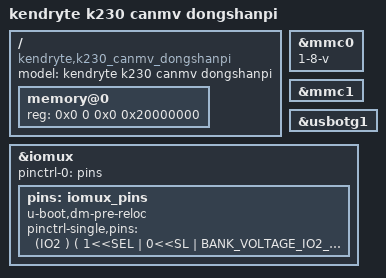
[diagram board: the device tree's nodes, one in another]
/* Copyright (c) 2023, Canaan Bright Sight Co., Ltd
 *
 * Redistribution and use in source and binary forms, with or without
 * modification, are permitted provided that the following conditions are met:
 * 1. Redistributions of source code must retain the above copyright
 * notice, this list of conditions and the following disclaimer.
 * 2. Redistributions in binary form must reproduce the above copyright
 * notice, this list of conditions and the following disclaimer in the
 * documentation and/or other materials provided with the distribution.
 *
 * THIS SOFTWARE IS PROVIDED BY THE COPYRIGHT HOLDERS AND
 * CONTRIBUTORS "AS IS" AND ANY EXPRESS OR IMPLIED WARRANTIES,
 * INCLUDING, BUT NOT LIMITED TO, THE IMPLIED WARRANTIES OF
 * MERCHANTABILITY AND FITNESS FOR A PARTICULAR PURPOSE ARE
 * DISCLAIMED. IN NO EVENT SHALL THE COPYRIGHT HOLDER OR
 * CONTRIBUTORS BE LIABLE FOR ANY DIRECT, INDIRECT, INCIDENTAL,
 * SPECIAL, EXEMPLARY, OR CONSEQUENTIAL DAMAGES (INCLUDING,
 * BUT NOT LIMITED TO, PROCUREMENT OF SUBSTITUTE GOODS OR
 * SERVICES; LOSS OF USE, DATA, OR PROFITS; OR BUSINESS
 * INTERRUPTION) HOWEVER CAUSED AND ON ANY THEORY OF LIABILITY,
 * WHETHER IN CONTRACT, STRICT LIABILITY, OR TORT (INCLUDING
 * NEGLIGENCE OR OTHERWISE) ARISING IN ANY WAY OUT OF THE USE
 * OF THIS SOFTWARE, EVEN IF ADVISED OF THE POSSIBILITY OF SUCH DAMAGE.
 */
/dts-v1/;
#include <dt-bindings/pinctrl/k230_evb.h>

#define BANK_VOLTAGE_IO0_IO1	 K230_MSC_1V8  // FIXED
#define BANK_VOLTAGE_IO2_IO13	 K230_MSC_3V3
#define BANK_VOLTAGE_IO14_IO25	 K230_MSC_3V3
#define BANK_VOLTAGE_IO26_IO37	 K230_MSC_3V3
#define BANK_VOLTAGE_IO38_IO49	 K230_MSC_3V3
#define BANK_VOLTAGE_IO50_IO61	 K230_MSC_3V3
#define BANK_VOLTAGE_IO62_IO63	 K230_MSC_3V3
#include "k230.dtsi"

/ {
	model = "kendryte k230 canmv dongshanpi";
	compatible = "kendryte,k230_canmv_dongshanpi";

	memory@0 {
		device_type = "memory";
		reg = <
				0x0 0 0x0 0x20000000
			  >;
	};
};

&mmc0 {
	1-8-v;
	status = "okay";
};

&mmc1 {
	status = "okay";
};

&usbotg1 {
	status = "okay";
};

&iomux {
	pinctrl-names = "default";
	pinctrl-0 = <&pins>;

//	Please pay attention to the bank voltage! will damage the chip.
	pins: iomux_pins {
		u-boot,dm-pre-reloc;
		pinctrl-single,pins = <

		// JTAG -> J5
		(IO2 ) ( 1<<SEL | 0<<SL | BANK_VOLTAGE_IO2_IO13 <<MSC | 1<<IE | 0<<OE | 0<<PU | 1<<PD | 4<<DS | 1<<ST )
		(IO3 ) ( 1<<SEL | 0<<SL | BANK_VOLTAGE_IO2_IO13 <<MSC | 1<<IE | 0<<OE | 0<<PU | 0<<PD | 4<<DS | 0<<ST )
		(IO4 ) ( 1<<SEL | 0<<SL | BANK_VOLTAGE_IO2_IO13 <<MSC | 0<<IE | 1<<OE | 0<<PU | 0<<PD | 4<<DS | 0<<ST )
		(IO5 ) ( 1<<SEL | 0<<SL | BANK_VOLTAGE_IO2_IO13 <<MSC | 1<<IE | 1<<OE | 0<<PU | 0<<PD | 4<<DS | 0<<ST )
		(IO6 ) ( 1<<SEL | 0<<SL | BANK_VOLTAGE_IO2_IO13 <<MSC | 1<<IE | 1<<OE | 0<<PU | 0<<PD | 4<<DS | 0<<ST )

		// I2C4 -> CSI2
		(IO7) ( 2<<SEL | 0<<SL | BANK_VOLTAGE_IO2_IO13<<MSC | 1<<IE | 1<<OE | 1<<PU | 0<<PD | 7<<DS | 1<<ST )
		(IO8) ( 2<<SEL | 0<<SL | BANK_VOLTAGE_IO2_IO13<<MSC | 1<<IE | 1<<OE | 1<<PU | 0<<PD | 7<<DS | 1<<ST )

		// GPIO -> CSI0
		(IO9 ) ( 0<<SEL | 0<<SL | BANK_VOLTAGE_IO2_IO13 <<MSC | 1<<IE | 1<<OE | 0<<PU | 0<<PD | 7<<DS | 1<<ST )
		(IO10) ( 0<<SEL | 0<<SL | BANK_VOLTAGE_IO2_IO13 <<MSC | 1<<IE | 1<<OE | 0<<PU | 0<<PD | 7<<DS | 1<<ST )
		//  GPIO -> CSI1
		(IO11) ( 0<<SEL | 0<<SL | BANK_VOLTAGE_IO2_IO13 <<MSC | 1<<IE | 1<<OE | 0<<PU | 0<<PD | 7<<DS | 1<<ST )
		(IO12) ( 0<<SEL | 0<<SL | BANK_VOLTAGE_IO2_IO13 <<MSC | 1<<IE | 1<<OE | 0<<PU | 0<<PD | 7<<DS | 1<<ST )

		// CAM2_MCLK -> CSI2
		(IO13) ( 1<<SEL | 0<<SL | BANK_VOLTAGE_IO2_IO13 <<MSC | 0<<IE | 1<<OE | 0<<PU | 1<<PD | 4<<DS | 1<<ST )

		// GPIO -> J10
		(IO14) ( 0<<SEL | 0<<SL | BANK_VOLTAGE_IO14_IO25<<MSC | 1<<IE | 1<<OE | 0<<PU | 0<<PD | 7<<DS | 1<<ST )
		(IO15) ( 0<<SEL | 0<<SL | BANK_VOLTAGE_IO14_IO25<<MSC | 1<<IE | 1<<OE | 0<<PU | 0<<PD | 7<<DS | 1<<ST )
		(IO16) ( 0<<SEL | 0<<SL | BANK_VOLTAGE_IO14_IO25<<MSC | 1<<IE | 1<<OE | 0<<PU | 0<<PD | 7<<DS | 1<<ST )
		(IO17) ( 0<<SEL | 0<<SL | BANK_VOLTAGE_IO14_IO25<<MSC | 1<<IE | 1<<OE | 0<<PU | 0<<PD | 7<<DS | 1<<ST )
		(IO18) ( 0<<SEL | 0<<SL | BANK_VOLTAGE_IO14_IO25<<MSC | 1<<IE | 1<<OE | 0<<PU | 0<<PD | 7<<DS | 1<<ST )
		(IO19) ( 0<<SEL | 0<<SL | BANK_VOLTAGE_IO14_IO25<<MSC | 1<<IE | 1<<OE | 0<<PU | 0<<PD | 7<<DS | 1<<ST )
		(IO20) ( 0<<SEL | 0<<SL | BANK_VOLTAGE_IO14_IO25<<MSC | 1<<IE | 1<<OE | 0<<PU | 0<<PD | 7<<DS | 1<<ST )
		
        // CAM2_RST -> CSI2
		(IO21) ( 0<<SEL | 0<<SL | BANK_VOLTAGE_IO14_IO25<<MSC | 1<<IE | 1<<OE | 0<<PU | 0<<PD | 7<<DS | 1<<ST )
		
        // LCD_RESET -> DSI
		(IO22) ( 0<<SEL | 0<<SL | BANK_VOLTAGE_IO14_IO25<<MSC | 1<<IE | 1<<OE | 0<<PU | 0<<PD | 7<<DS | 1<<ST )
		// CTP_INT -> DSI
		(IO23) ( 0<<SEL | 0<<SL | BANK_VOLTAGE_IO14_IO25<<MSC | 1<<IE | 1<<OE | 0<<PU | 0<<PD | 7<<DS | 1<<ST )
		// CTP_RST -> DSI
		(IO24) ( 0<<SEL | 0<<SL | BANK_VOLTAGE_IO14_IO25<<MSC | 1<<IE | 1<<OE | 0<<PU | 0<<PD | 7<<DS | 1<<ST )
		// LCD_PWM -> DSI
		(IO25) ( 0<<SEL | 0<<SL | BANK_VOLTAGE_IO14_IO25<<MSC | 1<<IE | 1<<OE | 0<<PU | 0<<PD | 7<<DS | 1<<ST )

		// GPIO -> J10
		(IO26) ( 0<<SEL | 0<<SL | BANK_VOLTAGE_IO26_IO37<<MSC | 1<<IE | 1<<OE | 0<<PU | 0<<PD | 7<<DS | 1<<ST )
		(IO27) ( 0<<SEL | 0<<SL | BANK_VOLTAGE_IO26_IO37<<MSC | 1<<IE | 1<<OE | 0<<PU | 0<<PD | 7<<DS | 1<<ST )
		(IO28) ( 0<<SEL | 0<<SL | BANK_VOLTAGE_IO26_IO37<<MSC | 1<<IE | 1<<OE | 0<<PU | 0<<PD | 7<<DS | 1<<ST )
		(IO29) ( 0<<SEL | 0<<SL | BANK_VOLTAGE_IO26_IO37<<MSC | 1<<IE | 1<<OE | 0<<PU | 0<<PD | 7<<DS | 1<<ST )
		(IO30) ( 0<<SEL | 0<<SL | BANK_VOLTAGE_IO26_IO37<<MSC | 1<<IE | 1<<OE | 0<<PU | 0<<PD | 7<<DS | 1<<ST )
		(IO31) ( 0<<SEL | 0<<SL | BANK_VOLTAGE_IO26_IO37<<MSC | 1<<IE | 1<<OE | 0<<PU | 0<<PD | 7<<DS | 1<<ST )
		(IO32) ( 0<<SEL | 0<<SL | BANK_VOLTAGE_IO26_IO37<<MSC | 1<<IE | 1<<OE | 0<<PU | 0<<PD | 7<<DS | 1<<ST )
		(IO33) ( 0<<SEL | 0<<SL | BANK_VOLTAGE_IO26_IO37<<MSC | 1<<IE | 1<<OE | 0<<PU | 0<<PD | 7<<DS | 1<<ST )
		(IO34) ( 0<<SEL | 0<<SL | BANK_VOLTAGE_IO26_IO37<<MSC | 1<<IE | 1<<OE | 0<<PU | 0<<PD | 7<<DS | 1<<ST )
		(IO35) ( 0<<SEL | 0<<SL | BANK_VOLTAGE_IO26_IO37<<MSC | 1<<IE | 1<<OE | 0<<PU | 0<<PD | 7<<DS | 1<<ST )
		
        // CTP_SCL -> DSI
		(IO36) ( 1<<SEL | 0<<SL | BANK_VOLTAGE_IO26_IO37<<MSC | 1<<IE | 1<<OE | 1<<PU | 0<<PD | 7<<DS | 1<<ST )
		// CTP_SDA -> DSI
		(IO37) ( 1<<SEL | 0<<SL | BANK_VOLTAGE_IO26_IO37<<MSC | 1<<IE | 1<<OE | 1<<PU | 0<<PD | 7<<DS | 1<<ST )

		// UART0 -> CH342F
		(IO38) ( 1<<SEL | 0<<SL | BANK_VOLTAGE_IO38_IO49<<MSC | 0<<IE | 1<<OE | 0<<PU | 0<<PD | 7<<DS | 1<<ST )
		(IO39) ( 1<<SEL | 0<<SL | BANK_VOLTAGE_IO38_IO49<<MSC | 1<<IE | 0<<OE | 0<<PU | 0<<PD | 7<<DS | 1<<ST )

		// I2C1_SCL -> CSI1
		(IO40) ( 2<<SEL | 0<<SL | BANK_VOLTAGE_IO38_IO49<<MSC | 1<<IE | 1<<OE | 1<<PU | 0<<PD | 7<<DS | 1<<ST )
		// I2C1_SDA -> CSI1
		(IO41) ( 2<<SEL | 0<<SL | BANK_VOLTAGE_IO38_IO49<<MSC | 1<<IE | 1<<OE | 1<<PU | 0<<PD | 7<<DS | 1<<ST )

		// GPIO -> J10
		(IO42) ( 0<<SEL | 0<<SL | BANK_VOLTAGE_IO38_IO49<<MSC | 1<<IE | 1<<OE | 0<<PU | 0<<PD | 7<<DS | 1<<ST )
		(IO43) ( 0<<SEL | 0<<SL | BANK_VOLTAGE_IO38_IO49<<MSC | 1<<IE | 1<<OE | 0<<PU | 0<<PD | 7<<DS | 1<<ST )
		(IO44) ( 0<<SEL | 0<<SL | BANK_VOLTAGE_IO38_IO49<<MSC | 1<<IE | 1<<OE | 1<<PU | 0<<PD | 7<<DS | 1<<ST )
		(IO45) ( 0<<SEL | 0<<SL | BANK_VOLTAGE_IO38_IO49<<MSC | 1<<IE | 1<<OE | 1<<PU | 0<<PD | 7<<DS | 1<<ST )

		// GPIO -> KEY1
		(IO46) ( 0<<SEL | 0<<SL | BANK_VOLTAGE_IO38_IO49<<MSC | 1<<IE | 0<<OE | 0<<PU | 0<<PD | 7<<DS | 1<<ST )
		// GPIO -> KEY2
		(IO47) ( 0<<SEL | 0<<SL | BANK_VOLTAGE_IO38_IO49<<MSC | 1<<IE | 0<<OE | 0<<PU | 0<<PD | 7<<DS | 1<<ST )

		// IIC0 -> CSI0
		(IO48) ( 3<<SEL | 0<<SL | BANK_VOLTAGE_IO38_IO49<<MSC | 1<<IE | 1<<OE | 1<<PU | 0<<PD | 7<<DS | 1<<ST )
		(IO49) ( 3<<SEL | 0<<SL | BANK_VOLTAGE_IO38_IO49<<MSC | 1<<IE | 1<<OE | 1<<PU | 0<<PD | 7<<DS | 1<<ST )

		// UART3 -> CH342F
		(IO50) ( 1<<SEL | 0<<SL | BANK_VOLTAGE_IO50_IO61<<MSC | 0<<IE | 1<<OE | 0<<PU | 0<<PD | 7<<DS | 1<<ST )
		(IO51) ( 1<<SEL | 0<<SL | BANK_VOLTAGE_IO50_IO61<<MSC | 1<<IE | 0<<OE | 0<<PU | 0<<PD | 7<<DS | 1<<ST )

		// GPIO -> J10
		(IO52) ( 0<<SEL | 0<<SL | BANK_VOLTAGE_IO50_IO61<<MSC | 1<<IE | 1<<OE | 0<<PU | 0<<PD | 7<<DS | 1<<ST )
		
        // SD_DET
		(IO53) ( 0<<SEL | 0<<SL | BANK_VOLTAGE_IO50_IO61<<MSC | 1<<IE | 1<<OE | 0<<PU | 0<<PD | 7<<DS | 1<<ST )

		// MMC1 -> TFCARD
		(IO54) ( 2<<SEL | 0<<SL | BANK_VOLTAGE_IO50_IO61<<MSC | 1<<IE | 1<<OE | 1<<PU | 0<<PD | 7<<DS | 1<<ST )
		(IO55) ( 2<<SEL | 0<<SL | BANK_VOLTAGE_IO50_IO61<<MSC | 0<<IE | 1<<OE | 0<<PU | 0<<PD | 7<<DS | 1<<ST )
		(IO56) ( 2<<SEL | 0<<SL | BANK_VOLTAGE_IO50_IO61<<MSC | 1<<IE | 1<<OE | 1<<PU | 0<<PD | 7<<DS | 1<<ST )
		(IO57) ( 2<<SEL | 0<<SL | BANK_VOLTAGE_IO50_IO61<<MSC | 1<<IE | 1<<OE | 1<<PU | 0<<PD | 7<<DS | 1<<ST )
		(IO58) ( 2<<SEL | 0<<SL | BANK_VOLTAGE_IO50_IO61<<MSC | 1<<IE | 1<<OE | 1<<PU | 0<<PD | 7<<DS | 1<<ST )
		(IO59) ( 2<<SEL | 0<<SL | BANK_VOLTAGE_IO50_IO61<<MSC | 1<<IE | 1<<OE | 1<<PU | 0<<PD | 7<<DS | 1<<ST )

		// GPIO60 -> CSI1
		(IO60) ( 0<<SEL | 0<<SL | BANK_VOLTAGE_IO50_IO61<<MSC | 1<<IE | 1<<OE | 1<<PU | 0<<PD | 7<<DS | 1<<ST )
		// GPIO60 -> CSI0
		(IO61) ( 0<<SEL | 0<<SL | BANK_VOLTAGE_IO50_IO61<<MSC | 1<<IE | 1<<OE | 1<<PU | 0<<PD | 7<<DS | 1<<ST )

		// GPIO -> J10
		(IO62) ( 0<<SEL | 0<<SL | BANK_VOLTAGE_IO62_IO63<<MSC | 1<<IE | 1<<OE | 0<<PU | 0<<PD | 7<<DS | 1<<ST )
		(IO63) ( 0<<SEL | 0<<SL | BANK_VOLTAGE_IO62_IO63<<MSC | 1<<IE | 1<<OE | 0<<PU | 0<<PD | 7<<DS | 1<<ST )
		>;
	};
};
